VERSION "pcm-protocol-0.4"

NS_ :

BS_:

BU_: HOST PCM0 PCM1

VAL_TABLE_ OutRequest 3 "RESERVED" 2 "ON" 1 "OFF" 0 "RELEASE" ;
VAL_TABLE_ OutState 3 "FAULT" 2 "PWM" 1 "ON" 0 "OFF" ;
VAL_TABLE_ OutSource 3 "OVERRIDE" 2 "CAN" 1 "RULE" 0 "DEFAULT" ;
VAL_TABLE_ SlotClass 3 "L" 2 "M" 1 "S" 0 "EMPTY" ;
VAL_TABLE_ FaultCode 13 "OVERVOLTAGE" 12 "FEEDBACK_MISMATCH" 11 "RUN_LIMIT" 10 "RETRY_WAIT" 9 "SLOT_MISMATCH" 8 "UNDERVOLTAGE" 7 "LOAD_SHED" 6 "LATCHED" 5 "EXT_VOLTAGE" 4 "OPEN_LOAD" 3 "OVERTEMP" 2 "SHORT" 1 "OVERCURRENT" 0 "NONE" ;
VAL_TABLE_ ConfigOp 5 "FACTORY_RESET" 4 "REVERT" 3 "COMMIT" 2 "WRITE" 1 "READ" 0 "NOP" ;
VAL_TABLE_ ConfigStatus 5 "LOCKED" 4 "BUSY" 3 "READ_ONLY" 2 "OUT_OF_RANGE" 1 "UNKNOWN_PARAM" 0 "OK" ;
VAL_TABLE_ ResetReason 5 "FW_UPDATE" 4 "PIN" 3 "SOFTWARE" 2 "WATCHDOG" 1 "BROWN_OUT" 0 "POWER_ON" ;

BO_ 1696 PCM0_Command: 8 HOST
 SG_ OUT1_Req : 0|2@1+ (1,0) [0|3] "" PCM0
 SG_ OUT2_Req : 2|2@1+ (1,0) [0|3] "" PCM0
 SG_ OUT3_Req : 4|2@1+ (1,0) [0|3] "" PCM0
 SG_ OUT4_Req : 6|2@1+ (1,0) [0|3] "" PCM0
 SG_ OUT1_FaultReset : 8|1@1+ (1,0) [0|1] "" PCM0
 SG_ OUT2_FaultReset : 9|1@1+ (1,0) [0|1] "" PCM0
 SG_ OUT3_FaultReset : 10|1@1+ (1,0) [0|1] "" PCM0
 SG_ OUT4_FaultReset : 11|1@1+ (1,0) [0|1] "" PCM0
 SG_ Cmd_AliveCounter : 12|4@1+ (1,0) [0|15] "" PCM0
 SG_ OUT1_Duty : 16|8@1+ (0.5,0) [0|127.5] "%" PCM0
 SG_ OUT2_Duty : 24|8@1+ (0.5,0) [0|127.5] "%" PCM0
 SG_ OUT3_Duty : 32|8@1+ (0.5,0) [0|127.5] "%" PCM0
 SG_ OUT4_Duty : 40|8@1+ (0.5,0) [0|127.5] "%" PCM0
 SG_ VIN1 : 48|1@1+ (1,0) [0|1] "" PCM0
 SG_ VIN2 : 49|1@1+ (1,0) [0|1] "" PCM0
 SG_ VIN3 : 50|1@1+ (1,0) [0|1] "" PCM0
 SG_ VIN4 : 51|1@1+ (1,0) [0|1] "" PCM0
 SG_ VIN5 : 52|1@1+ (1,0) [0|1] "" PCM0
 SG_ VIN6 : 53|1@1+ (1,0) [0|1] "" PCM0
 SG_ VIN7 : 54|1@1+ (1,0) [0|1] "" PCM0
 SG_ VIN8 : 55|1@1+ (1,0) [0|1] "" PCM0
 SG_ AUX1_Req : 56|2@1+ (1,0) [0|3] "" PCM0
 SG_ AUX2_Req : 58|2@1+ (1,0) [0|3] "" PCM0
 SG_ AUX3_Req : 60|2@1+ (1,0) [0|3] "" PCM0
 SG_ AUX4_Req : 62|2@1+ (1,0) [0|3] "" PCM0

BO_ 1697 PCM0_Status: 8 PCM0
 SG_ OUT1_State : 0|2@1+ (1,0) [0|3] "" HOST
 SG_ OUT2_State : 2|2@1+ (1,0) [0|3] "" HOST
 SG_ OUT3_State : 4|2@1+ (1,0) [0|3] "" HOST
 SG_ OUT4_State : 6|2@1+ (1,0) [0|3] "" HOST
 SG_ IN1_Active : 8|1@1+ (1,0) [0|1] "" HOST
 SG_ IN2_Active : 9|1@1+ (1,0) [0|1] "" HOST
 SG_ IN3_Active : 10|1@1+ (1,0) [0|1] "" HOST
 SG_ IN4_Active : 11|1@1+ (1,0) [0|1] "" HOST
 SG_ IN5_Active : 12|1@1+ (1,0) [0|1] "" HOST
 SG_ IN6_Active : 13|1@1+ (1,0) [0|1] "" HOST
 SG_ IN7_Active : 14|1@1+ (1,0) [0|1] "" HOST
 SG_ IN8_Active : 15|1@1+ (1,0) [0|1] "" HOST
 SG_ VBAT : 16|8@1+ (0.1,0) [0|25.5] "V" HOST
 SG_ BoardTemp : 24|8@1+ (1,-40) [-40|215] "degC" HOST
 SG_ OUT1_Source : 32|2@1+ (1,0) [0|3] "" HOST
 SG_ OUT2_Source : 34|2@1+ (1,0) [0|3] "" HOST
 SG_ OUT3_Source : 36|2@1+ (1,0) [0|3] "" HOST
 SG_ OUT4_Source : 38|2@1+ (1,0) [0|3] "" HOST
 SG_ IGN_Active : 40|1@1+ (1,0) [0|1] "" HOST
 SG_ SleepPending : 41|1@1+ (1,0) [0|1] "" HOST
 SG_ HostPresent : 42|1@1+ (1,0) [0|1] "" HOST
 SG_ ConfigDirty : 43|1@1+ (1,0) [0|1] "" HOST
 SG_ LoadShedActive : 44|1@1+ (1,0) [0|1] "" HOST
 SG_ ModuleBudgetLimit : 45|1@1+ (1,0) [0|1] "" HOST
 SG_ ThermalDerating : 46|1@1+ (1,0) [0|1] "" HOST
 SG_ VehicleSignalStale : 47|1@1+ (1,0) [0|1] "" HOST
 SG_ ModuleCurrent : 48|8@1+ (0.5,0) [0|127.5] "A" HOST
 SG_ AUX1_On : 56|1@1+ (1,0) [0|1] "" HOST
 SG_ AUX2_On : 57|1@1+ (1,0) [0|1] "" HOST
 SG_ AUX3_On : 58|1@1+ (1,0) [0|1] "" HOST
 SG_ AUX4_On : 59|1@1+ (1,0) [0|1] "" HOST
 SG_ Sts_AliveCounter : 60|4@1+ (1,0) [0|15] "" HOST

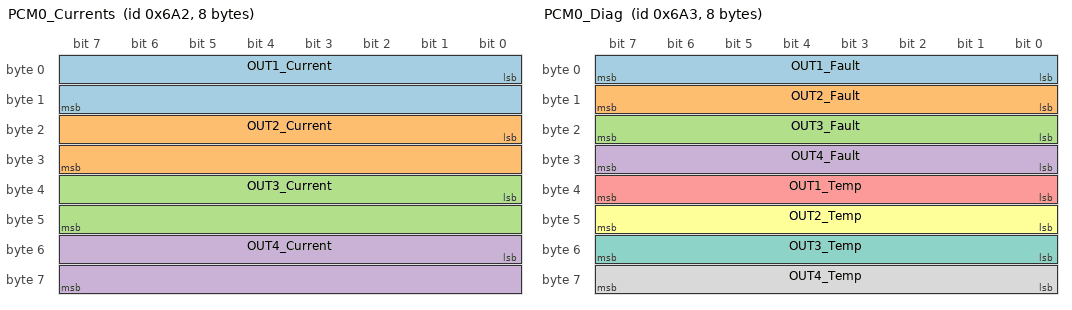
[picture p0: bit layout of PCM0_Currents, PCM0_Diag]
BO_ 1698 PCM0_Currents: 8 PCM0
 SG_ OUT1_Current : 0|16@1+ (0.01,0) [0|655.35] "A" HOST
 SG_ OUT2_Current : 16|16@1+ (0.01,0) [0|655.35] "A" HOST
 SG_ OUT3_Current : 32|16@1+ (0.01,0) [0|655.35] "A" HOST
 SG_ OUT4_Current : 48|16@1+ (0.01,0) [0|655.35] "A" HOST

BO_ 1699 PCM0_Diag: 8 PCM0
 SG_ OUT1_Fault : 0|8@1+ (1,0) [0|255] "" HOST
 SG_ OUT2_Fault : 8|8@1+ (1,0) [0|255] "" HOST
 SG_ OUT3_Fault : 16|8@1+ (1,0) [0|255] "" HOST
 SG_ OUT4_Fault : 24|8@1+ (1,0) [0|255] "" HOST
 SG_ OUT1_Temp : 32|8@1+ (1,-40) [-40|215] "degC" HOST
 SG_ OUT2_Temp : 40|8@1+ (1,-40) [-40|215] "degC" HOST
 SG_ OUT3_Temp : 48|8@1+ (1,-40) [-40|215] "degC" HOST
 SG_ OUT4_Temp : 56|8@1+ (1,-40) [-40|215] "degC" HOST

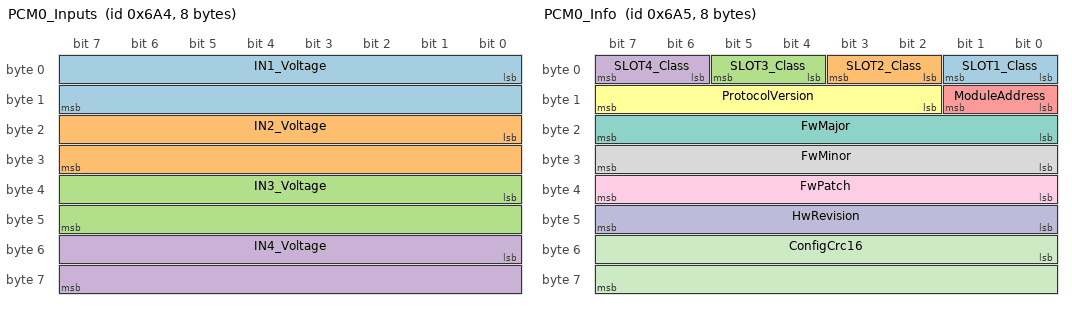
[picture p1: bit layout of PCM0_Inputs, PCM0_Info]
BO_ 1700 PCM0_Inputs: 8 PCM0
 SG_ IN1_Voltage : 0|16@1+ (0.001,0) [0|65.535] "V" HOST
 SG_ IN2_Voltage : 16|16@1+ (0.001,0) [0|65.535] "V" HOST
 SG_ IN3_Voltage : 32|16@1+ (0.001,0) [0|65.535] "V" HOST
 SG_ IN4_Voltage : 48|16@1+ (0.001,0) [0|65.535] "V" HOST

BO_ 1701 PCM0_Info: 8 PCM0
 SG_ SLOT1_Class : 0|2@1+ (1,0) [0|3] "" HOST
 SG_ SLOT2_Class : 2|2@1+ (1,0) [0|3] "" HOST
 SG_ SLOT3_Class : 4|2@1+ (1,0) [0|3] "" HOST
 SG_ SLOT4_Class : 6|2@1+ (1,0) [0|3] "" HOST
 SG_ ModuleAddress : 8|2@1+ (1,0) [0|3] "" HOST
 SG_ ProtocolVersion : 10|6@1+ (1,0) [0|63] "" HOST
 SG_ FwMajor : 16|8@1+ (1,0) [0|255] "" HOST
 SG_ FwMinor : 24|8@1+ (1,0) [0|255] "" HOST
 SG_ FwPatch : 32|8@1+ (1,0) [0|255] "" HOST
 SG_ HwRevision : 40|8@1+ (1,0) [0|255] "" HOST
 SG_ ConfigCrc16 : 48|16@1+ (1,0) [0|65535] "" HOST

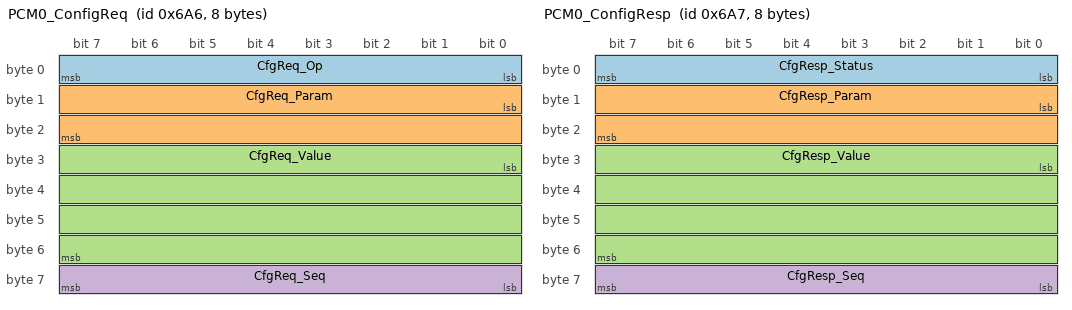
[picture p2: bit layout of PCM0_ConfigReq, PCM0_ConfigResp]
BO_ 1702 PCM0_ConfigReq: 8 HOST
 SG_ CfgReq_Op : 0|8@1+ (1,0) [0|255] "" PCM0
 SG_ CfgReq_Param : 8|16@1+ (1,0) [0|65535] "" PCM0
 SG_ CfgReq_Value : 24|32@1- (1,0) [-2147483648|2147483647] "" PCM0
 SG_ CfgReq_Seq : 56|8@1+ (1,0) [0|255] "" PCM0

BO_ 1703 PCM0_ConfigResp: 8 PCM0
 SG_ CfgResp_Status : 0|8@1+ (1,0) [0|255] "" HOST
 SG_ CfgResp_Param : 8|16@1+ (1,0) [0|65535] "" HOST
 SG_ CfgResp_Value : 24|32@1- (1,0) [-2147483648|2147483647] "" HOST
 SG_ CfgResp_Seq : 56|8@1+ (1,0) [0|255] "" HOST

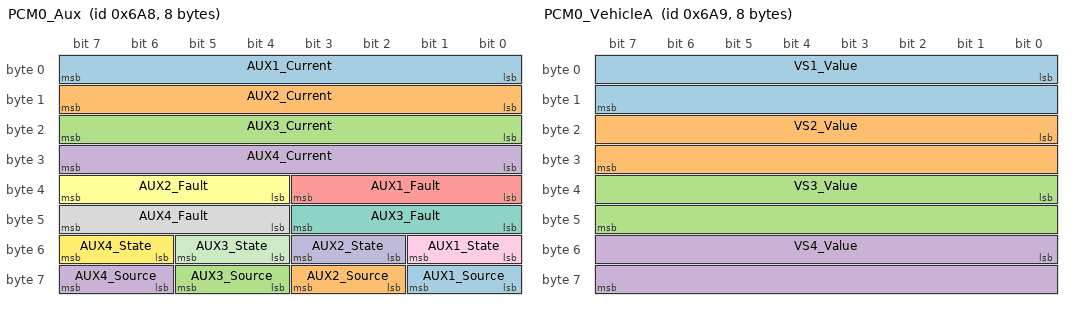
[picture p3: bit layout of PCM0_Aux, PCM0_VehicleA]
BO_ 1704 PCM0_Aux: 8 PCM0
 SG_ AUX1_Current : 0|8@1+ (0.02,0) [0|5.1] "A" HOST
 SG_ AUX2_Current : 8|8@1+ (0.02,0) [0|5.1] "A" HOST
 SG_ AUX3_Current : 16|8@1+ (0.02,0) [0|5.1] "A" HOST
 SG_ AUX4_Current : 24|8@1+ (0.02,0) [0|5.1] "A" HOST
 SG_ AUX1_Fault : 32|4@1+ (1,0) [0|15] "" HOST
 SG_ AUX2_Fault : 36|4@1+ (1,0) [0|15] "" HOST
 SG_ AUX3_Fault : 40|4@1+ (1,0) [0|15] "" HOST
 SG_ AUX4_Fault : 44|4@1+ (1,0) [0|15] "" HOST
 SG_ AUX1_State : 48|2@1+ (1,0) [0|3] "" HOST
 SG_ AUX2_State : 50|2@1+ (1,0) [0|3] "" HOST
 SG_ AUX3_State : 52|2@1+ (1,0) [0|3] "" HOST
 SG_ AUX4_State : 54|2@1+ (1,0) [0|3] "" HOST
 SG_ AUX1_Source : 56|2@1+ (1,0) [0|3] "" HOST
 SG_ AUX2_Source : 58|2@1+ (1,0) [0|3] "" HOST
 SG_ AUX3_Source : 60|2@1+ (1,0) [0|3] "" HOST
 SG_ AUX4_Source : 62|2@1+ (1,0) [0|3] "" HOST

BO_ 1705 PCM0_VehicleA: 8 PCM0
 SG_ VS1_Value : 0|16@1- (1,0) [-32768|32767] "" HOST
 SG_ VS2_Value : 16|16@1- (1,0) [-32768|32767] "" HOST
 SG_ VS3_Value : 32|16@1- (1,0) [-32768|32767] "" HOST
 SG_ VS4_Value : 48|16@1- (1,0) [-32768|32767] "" HOST

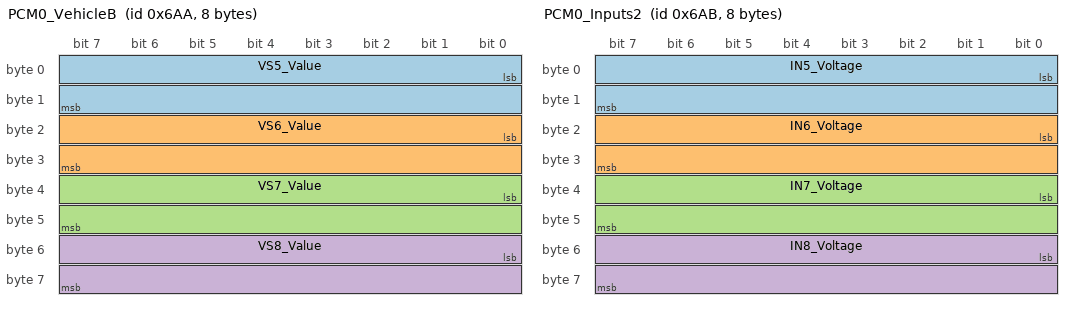
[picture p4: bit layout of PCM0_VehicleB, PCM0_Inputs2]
BO_ 1706 PCM0_VehicleB: 8 PCM0
 SG_ VS5_Value : 0|16@1- (1,0) [-32768|32767] "" HOST
 SG_ VS6_Value : 16|16@1- (1,0) [-32768|32767] "" HOST
 SG_ VS7_Value : 32|16@1- (1,0) [-32768|32767] "" HOST
 SG_ VS8_Value : 48|16@1- (1,0) [-32768|32767] "" HOST

BO_ 1707 PCM0_Inputs2: 8 PCM0
 SG_ IN5_Voltage : 0|16@1+ (0.001,0) [0|65.535] "V" HOST
 SG_ IN6_Voltage : 16|16@1+ (0.001,0) [0|65.535] "V" HOST
 SG_ IN7_Voltage : 32|16@1+ (0.001,0) [0|65.535] "V" HOST
 SG_ IN8_Voltage : 48|16@1+ (0.001,0) [0|65.535] "V" HOST

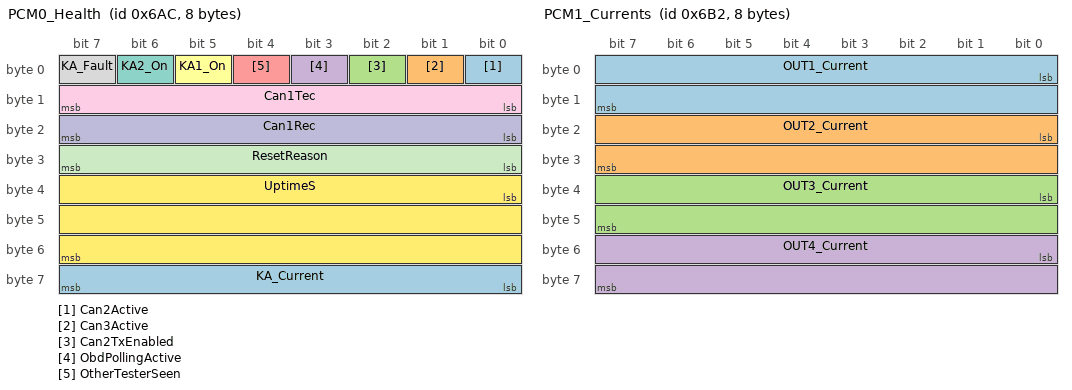
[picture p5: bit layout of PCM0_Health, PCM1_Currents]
BO_ 1708 PCM0_Health: 8 PCM0
 SG_ Can2Active : 0|1@1+ (1,0) [0|1] "" HOST
 SG_ Can3Active : 1|1@1+ (1,0) [0|1] "" HOST
 SG_ Can2TxEnabled : 2|1@1+ (1,0) [0|1] "" HOST
 SG_ ObdPollingActive : 3|1@1+ (1,0) [0|1] "" HOST
 SG_ OtherTesterSeen : 4|1@1+ (1,0) [0|1] "" HOST
 SG_ KA1_On : 5|1@1+ (1,0) [0|1] "" HOST
 SG_ KA2_On : 6|1@1+ (1,0) [0|1] "" HOST
 SG_ KA_Fault : 7|1@1+ (1,0) [0|1] "" HOST
 SG_ Can1Tec : 8|8@1+ (1,0) [0|255] "" HOST
 SG_ Can1Rec : 16|8@1+ (1,0) [0|255] "" HOST
 SG_ ResetReason : 24|8@1+ (1,0) [0|255] "" HOST
 SG_ UptimeS : 32|24@1+ (1,0) [0|16777215] "s" HOST
 SG_ KA_Current : 56|8@1+ (0.005,0) [0|1.275] "A" HOST

BO_ 1712 PCM1_Command: 8 HOST
 SG_ OUT1_Req : 0|2@1+ (1,0) [0|3] "" PCM1
 SG_ OUT2_Req : 2|2@1+ (1,0) [0|3] "" PCM1
 SG_ OUT3_Req : 4|2@1+ (1,0) [0|3] "" PCM1
 SG_ OUT4_Req : 6|2@1+ (1,0) [0|3] "" PCM1
 SG_ OUT1_FaultReset : 8|1@1+ (1,0) [0|1] "" PCM1
 SG_ OUT2_FaultReset : 9|1@1+ (1,0) [0|1] "" PCM1
 SG_ OUT3_FaultReset : 10|1@1+ (1,0) [0|1] "" PCM1
 SG_ OUT4_FaultReset : 11|1@1+ (1,0) [0|1] "" PCM1
 SG_ Cmd_AliveCounter : 12|4@1+ (1,0) [0|15] "" PCM1
 SG_ OUT1_Duty : 16|8@1+ (0.5,0) [0|127.5] "%" PCM1
 SG_ OUT2_Duty : 24|8@1+ (0.5,0) [0|127.5] "%" PCM1
 SG_ OUT3_Duty : 32|8@1+ (0.5,0) [0|127.5] "%" PCM1
 SG_ OUT4_Duty : 40|8@1+ (0.5,0) [0|127.5] "%" PCM1
 SG_ VIN1 : 48|1@1+ (1,0) [0|1] "" PCM1
 SG_ VIN2 : 49|1@1+ (1,0) [0|1] "" PCM1
 SG_ VIN3 : 50|1@1+ (1,0) [0|1] "" PCM1
 SG_ VIN4 : 51|1@1+ (1,0) [0|1] "" PCM1
 SG_ VIN5 : 52|1@1+ (1,0) [0|1] "" PCM1
 SG_ VIN6 : 53|1@1+ (1,0) [0|1] "" PCM1
 SG_ VIN7 : 54|1@1+ (1,0) [0|1] "" PCM1
 SG_ VIN8 : 55|1@1+ (1,0) [0|1] "" PCM1
 SG_ AUX1_Req : 56|2@1+ (1,0) [0|3] "" PCM1
 SG_ AUX2_Req : 58|2@1+ (1,0) [0|3] "" PCM1
 SG_ AUX3_Req : 60|2@1+ (1,0) [0|3] "" PCM1
 SG_ AUX4_Req : 62|2@1+ (1,0) [0|3] "" PCM1

BO_ 1713 PCM1_Status: 8 PCM1
 SG_ OUT1_State : 0|2@1+ (1,0) [0|3] "" HOST
 SG_ OUT2_State : 2|2@1+ (1,0) [0|3] "" HOST
 SG_ OUT3_State : 4|2@1+ (1,0) [0|3] "" HOST
 SG_ OUT4_State : 6|2@1+ (1,0) [0|3] "" HOST
 SG_ IN1_Active : 8|1@1+ (1,0) [0|1] "" HOST
 SG_ IN2_Active : 9|1@1+ (1,0) [0|1] "" HOST
 SG_ IN3_Active : 10|1@1+ (1,0) [0|1] "" HOST
 SG_ IN4_Active : 11|1@1+ (1,0) [0|1] "" HOST
 SG_ IN5_Active : 12|1@1+ (1,0) [0|1] "" HOST
 SG_ IN6_Active : 13|1@1+ (1,0) [0|1] "" HOST
 SG_ IN7_Active : 14|1@1+ (1,0) [0|1] "" HOST
 SG_ IN8_Active : 15|1@1+ (1,0) [0|1] "" HOST
 SG_ VBAT : 16|8@1+ (0.1,0) [0|25.5] "V" HOST
 SG_ BoardTemp : 24|8@1+ (1,-40) [-40|215] "degC" HOST
 SG_ OUT1_Source : 32|2@1+ (1,0) [0|3] "" HOST
 SG_ OUT2_Source : 34|2@1+ (1,0) [0|3] "" HOST
 SG_ OUT3_Source : 36|2@1+ (1,0) [0|3] "" HOST
 SG_ OUT4_Source : 38|2@1+ (1,0) [0|3] "" HOST
 SG_ IGN_Active : 40|1@1+ (1,0) [0|1] "" HOST
 SG_ SleepPending : 41|1@1+ (1,0) [0|1] "" HOST
 SG_ HostPresent : 42|1@1+ (1,0) [0|1] "" HOST
 SG_ ConfigDirty : 43|1@1+ (1,0) [0|1] "" HOST
 SG_ LoadShedActive : 44|1@1+ (1,0) [0|1] "" HOST
 SG_ ModuleBudgetLimit : 45|1@1+ (1,0) [0|1] "" HOST
 SG_ ThermalDerating : 46|1@1+ (1,0) [0|1] "" HOST
 SG_ VehicleSignalStale : 47|1@1+ (1,0) [0|1] "" HOST
 SG_ ModuleCurrent : 48|8@1+ (0.5,0) [0|127.5] "A" HOST
 SG_ AUX1_On : 56|1@1+ (1,0) [0|1] "" HOST
 SG_ AUX2_On : 57|1@1+ (1,0) [0|1] "" HOST
 SG_ AUX3_On : 58|1@1+ (1,0) [0|1] "" HOST
 SG_ AUX4_On : 59|1@1+ (1,0) [0|1] "" HOST
 SG_ Sts_AliveCounter : 60|4@1+ (1,0) [0|15] "" HOST

BO_ 1714 PCM1_Currents: 8 PCM1
 SG_ OUT1_Current : 0|16@1+ (0.01,0) [0|655.35] "A" HOST
 SG_ OUT2_Current : 16|16@1+ (0.01,0) [0|655.35] "A" HOST
 SG_ OUT3_Current : 32|16@1+ (0.01,0) [0|655.35] "A" HOST
 SG_ OUT4_Current : 48|16@1+ (0.01,0) [0|655.35] "A" HOST

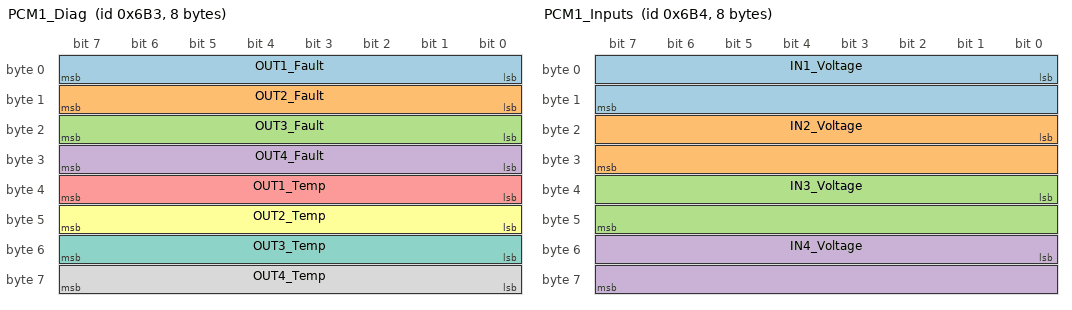
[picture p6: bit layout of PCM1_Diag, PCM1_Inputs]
BO_ 1715 PCM1_Diag: 8 PCM1
 SG_ OUT1_Fault : 0|8@1+ (1,0) [0|255] "" HOST
 SG_ OUT2_Fault : 8|8@1+ (1,0) [0|255] "" HOST
 SG_ OUT3_Fault : 16|8@1+ (1,0) [0|255] "" HOST
 SG_ OUT4_Fault : 24|8@1+ (1,0) [0|255] "" HOST
 SG_ OUT1_Temp : 32|8@1+ (1,-40) [-40|215] "degC" HOST
 SG_ OUT2_Temp : 40|8@1+ (1,-40) [-40|215] "degC" HOST
 SG_ OUT3_Temp : 48|8@1+ (1,-40) [-40|215] "degC" HOST
 SG_ OUT4_Temp : 56|8@1+ (1,-40) [-40|215] "degC" HOST

BO_ 1716 PCM1_Inputs: 8 PCM1
 SG_ IN1_Voltage : 0|16@1+ (0.001,0) [0|65.535] "V" HOST
 SG_ IN2_Voltage : 16|16@1+ (0.001,0) [0|65.535] "V" HOST
 SG_ IN3_Voltage : 32|16@1+ (0.001,0) [0|65.535] "V" HOST
 SG_ IN4_Voltage : 48|16@1+ (0.001,0) [0|65.535] "V" HOST

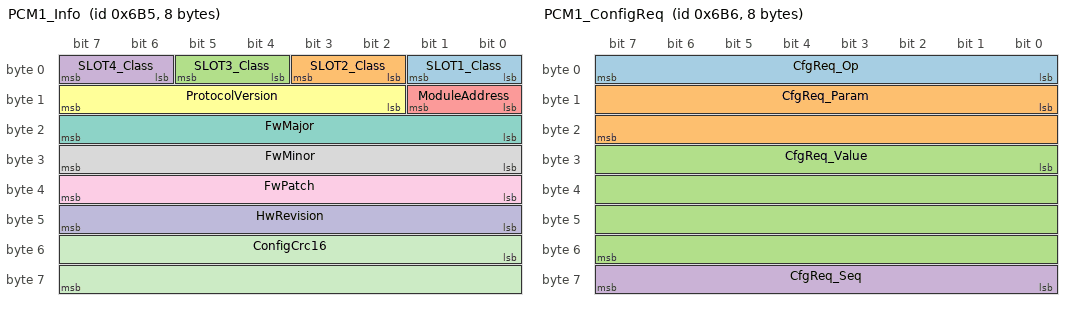
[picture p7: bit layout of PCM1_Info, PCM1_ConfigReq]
BO_ 1717 PCM1_Info: 8 PCM1
 SG_ SLOT1_Class : 0|2@1+ (1,0) [0|3] "" HOST
 SG_ SLOT2_Class : 2|2@1+ (1,0) [0|3] "" HOST
 SG_ SLOT3_Class : 4|2@1+ (1,0) [0|3] "" HOST
 SG_ SLOT4_Class : 6|2@1+ (1,0) [0|3] "" HOST
 SG_ ModuleAddress : 8|2@1+ (1,0) [0|3] "" HOST
 SG_ ProtocolVersion : 10|6@1+ (1,0) [0|63] "" HOST
 SG_ FwMajor : 16|8@1+ (1,0) [0|255] "" HOST
 SG_ FwMinor : 24|8@1+ (1,0) [0|255] "" HOST
 SG_ FwPatch : 32|8@1+ (1,0) [0|255] "" HOST
 SG_ HwRevision : 40|8@1+ (1,0) [0|255] "" HOST
 SG_ ConfigCrc16 : 48|16@1+ (1,0) [0|65535] "" HOST

BO_ 1718 PCM1_ConfigReq: 8 HOST
 SG_ CfgReq_Op : 0|8@1+ (1,0) [0|255] "" PCM1
 SG_ CfgReq_Param : 8|16@1+ (1,0) [0|65535] "" PCM1
 SG_ CfgReq_Value : 24|32@1- (1,0) [-2147483648|2147483647] "" PCM1
 SG_ CfgReq_Seq : 56|8@1+ (1,0) [0|255] "" PCM1

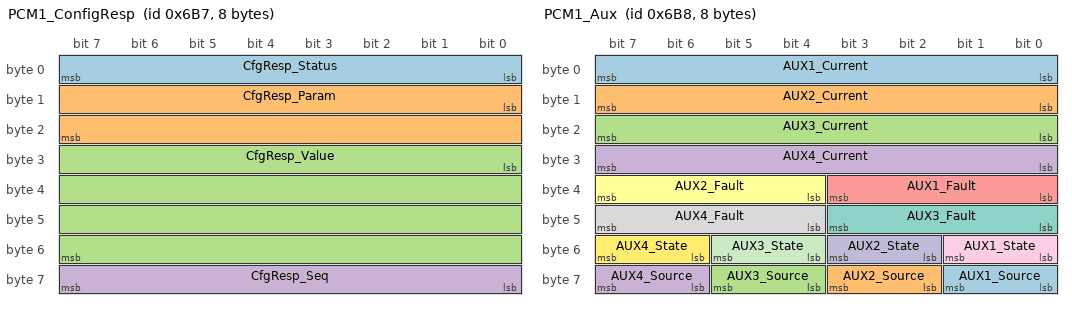
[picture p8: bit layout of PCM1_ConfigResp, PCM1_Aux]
BO_ 1719 PCM1_ConfigResp: 8 PCM1
 SG_ CfgResp_Status : 0|8@1+ (1,0) [0|255] "" HOST
 SG_ CfgResp_Param : 8|16@1+ (1,0) [0|65535] "" HOST
 SG_ CfgResp_Value : 24|32@1- (1,0) [-2147483648|2147483647] "" HOST
 SG_ CfgResp_Seq : 56|8@1+ (1,0) [0|255] "" HOST

BO_ 1720 PCM1_Aux: 8 PCM1
 SG_ AUX1_Current : 0|8@1+ (0.02,0) [0|5.1] "A" HOST
 SG_ AUX2_Current : 8|8@1+ (0.02,0) [0|5.1] "A" HOST
 SG_ AUX3_Current : 16|8@1+ (0.02,0) [0|5.1] "A" HOST
 SG_ AUX4_Current : 24|8@1+ (0.02,0) [0|5.1] "A" HOST
 SG_ AUX1_Fault : 32|4@1+ (1,0) [0|15] "" HOST
 SG_ AUX2_Fault : 36|4@1+ (1,0) [0|15] "" HOST
 SG_ AUX3_Fault : 40|4@1+ (1,0) [0|15] "" HOST
 SG_ AUX4_Fault : 44|4@1+ (1,0) [0|15] "" HOST
 SG_ AUX1_State : 48|2@1+ (1,0) [0|3] "" HOST
 SG_ AUX2_State : 50|2@1+ (1,0) [0|3] "" HOST
 SG_ AUX3_State : 52|2@1+ (1,0) [0|3] "" HOST
 SG_ AUX4_State : 54|2@1+ (1,0) [0|3] "" HOST
 SG_ AUX1_Source : 56|2@1+ (1,0) [0|3] "" HOST
 SG_ AUX2_Source : 58|2@1+ (1,0) [0|3] "" HOST
 SG_ AUX3_Source : 60|2@1+ (1,0) [0|3] "" HOST
 SG_ AUX4_Source : 62|2@1+ (1,0) [0|3] "" HOST

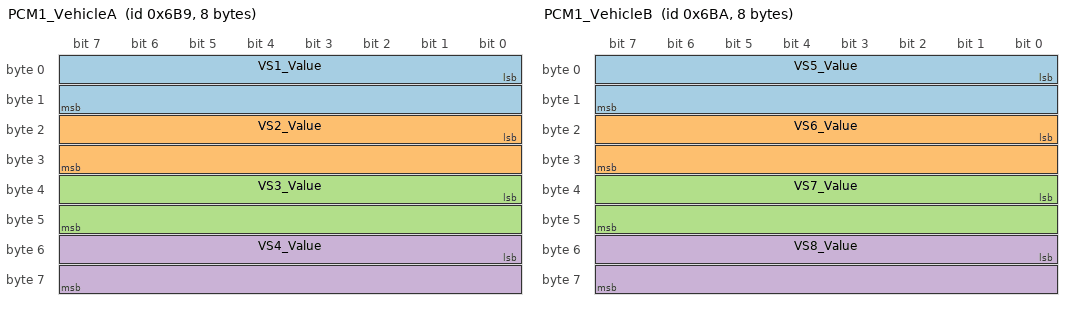
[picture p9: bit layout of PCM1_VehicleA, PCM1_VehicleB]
BO_ 1721 PCM1_VehicleA: 8 PCM1
 SG_ VS1_Value : 0|16@1- (1,0) [-32768|32767] "" HOST
 SG_ VS2_Value : 16|16@1- (1,0) [-32768|32767] "" HOST
 SG_ VS3_Value : 32|16@1- (1,0) [-32768|32767] "" HOST
 SG_ VS4_Value : 48|16@1- (1,0) [-32768|32767] "" HOST

BO_ 1722 PCM1_VehicleB: 8 PCM1
 SG_ VS5_Value : 0|16@1- (1,0) [-32768|32767] "" HOST
 SG_ VS6_Value : 16|16@1- (1,0) [-32768|32767] "" HOST
 SG_ VS7_Value : 32|16@1- (1,0) [-32768|32767] "" HOST
 SG_ VS8_Value : 48|16@1- (1,0) [-32768|32767] "" HOST

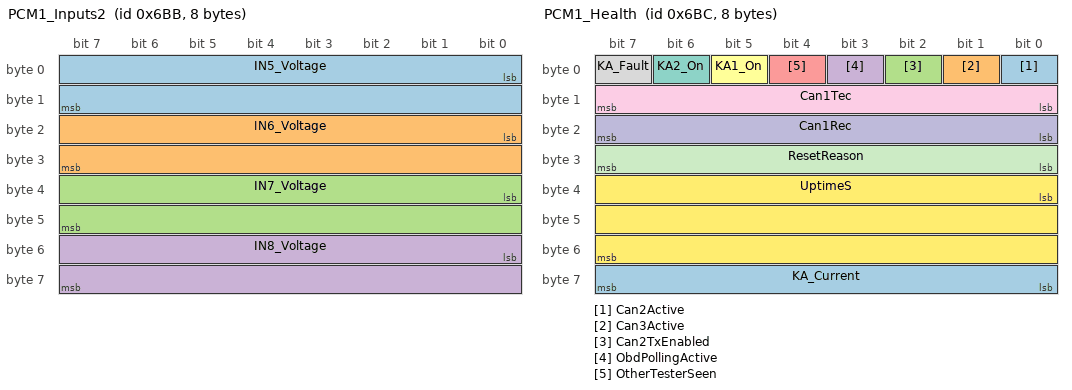
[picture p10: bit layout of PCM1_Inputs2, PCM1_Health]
BO_ 1723 PCM1_Inputs2: 8 PCM1
 SG_ IN5_Voltage : 0|16@1+ (0.001,0) [0|65.535] "V" HOST
 SG_ IN6_Voltage : 16|16@1+ (0.001,0) [0|65.535] "V" HOST
 SG_ IN7_Voltage : 32|16@1+ (0.001,0) [0|65.535] "V" HOST
 SG_ IN8_Voltage : 48|16@1+ (0.001,0) [0|65.535] "V" HOST

BO_ 1724 PCM1_Health: 8 PCM1
 SG_ Can2Active : 0|1@1+ (1,0) [0|1] "" HOST
 SG_ Can3Active : 1|1@1+ (1,0) [0|1] "" HOST
 SG_ Can2TxEnabled : 2|1@1+ (1,0) [0|1] "" HOST
 SG_ ObdPollingActive : 3|1@1+ (1,0) [0|1] "" HOST
 SG_ OtherTesterSeen : 4|1@1+ (1,0) [0|1] "" HOST
 SG_ KA1_On : 5|1@1+ (1,0) [0|1] "" HOST
 SG_ KA2_On : 6|1@1+ (1,0) [0|1] "" HOST
 SG_ KA_Fault : 7|1@1+ (1,0) [0|1] "" HOST
 SG_ Can1Tec : 8|8@1+ (1,0) [0|255] "" HOST
 SG_ Can1Rec : 16|8@1+ (1,0) [0|255] "" HOST
 SG_ ResetReason : 24|8@1+ (1,0) [0|255] "" HOST
 SG_ UptimeS : 32|24@1+ (1,0) [0|16777215] "s" HOST
 SG_ KA_Current : 56|8@1+ (0.005,0) [0|1.275] "A" HOST

CM_ "Power control modules, addresses 0-1, default base ID 0x6A0; module n uses base + 0x10*n. Generated from pcm.dbc by tools/gen_dbc.py - edit pcm.dbc, not this file.";
CM_ BO_ 1696 "Host to module. Send every 100 ms while controlling outputs; 500 ms without a frame whose alive counter changed is a host timeout.";
CM_ BO_ 1712 "Host to module. Send every 100 ms while controlling outputs; 500 ms without a frame whose alive counter changed is a host timeout.";
CM_ SG_ 1696 OUT1_Req "RELEASE hands the output back to the rule engine.";
CM_ SG_ 1712 OUT1_Req "RELEASE hands the output back to the rule engine.";
CM_ SG_ 1696 OUT1_Duty "PWM duty when Req is ON. 200 = 100 %. 255 = use the configured default.";
CM_ SG_ 1712 OUT1_Duty "PWM duty when Req is ON. 200 = 100 %. 255 = use the configured default.";
CM_ SG_ 1696 OUT1_FaultReset "Rising edge clears a latched fault on OUT1.";
CM_ SG_ 1712 OUT1_FaultReset "Rising edge clears a latched fault on OUT1.";
CM_ SG_ 1696 Cmd_AliveCounter "Increment by 1 every frame, wrapping at 15.";
CM_ SG_ 1712 Cmd_AliveCounter "Increment by 1 every frame, wrapping at 15.";
CM_ SG_ 1696 VIN1 "Virtual input for the rule engine, e.g. a CAN switch-panel button.";
CM_ SG_ 1712 VIN1 "Virtual input for the rule engine, e.g. a CAN switch-panel button.";
CM_ SG_ 1696 AUX1_Req "Same coding as OUT1_Req. AUX outputs are on/off only.";
CM_ SG_ 1712 AUX1_Req "Same coding as OUT1_Req. AUX outputs are on/off only.";
CM_ BO_ 1697 "Module to host. 100 ms, and on any state change (at most every 10 ms).";
CM_ BO_ 1713 "Module to host. 100 ms, and on any state change (at most every 10 ms).";
CM_ SG_ 1697 ConfigDirty "RAM configuration differs from flash; send ConfigReq COMMIT to persist.";
CM_ SG_ 1713 ConfigDirty "RAM configuration differs from flash; send ConfigReq COMMIT to persist.";
CM_ SG_ 1697 ModuleCurrent "Sum of all main and AUX output currents.";
CM_ SG_ 1713 ModuleCurrent "Sum of all main and AUX output currents.";
CM_ BO_ 1698 "Module to host, 100 ms.";
CM_ BO_ 1714 "Module to host, 100 ms.";
CM_ BO_ 1699 "Module to host, 1 s and on change. Temp 255 (raw) = not measured for this cell.";
CM_ BO_ 1715 "Module to host, 1 s and on change. Temp 255 (raw) = not measured for this cell.";
CM_ SG_ 1699 OUT1_Fault "FaultCode value table.";
CM_ SG_ 1715 OUT1_Fault "FaultCode value table.";
CM_ BO_ 1700 "Module to host, 100 ms. Voltage at input pins 1-4.";
CM_ BO_ 1716 "Module to host, 100 ms. Voltage at input pins 1-4.";
CM_ BO_ 1701 "Module to host, 1 s.";
CM_ BO_ 1717 "Module to host, 1 s.";
CM_ BO_ 1702 "Host to module configuration access. One request in flight; match responses by Seq.";
CM_ BO_ 1718 "Host to module configuration access. One request in flight; match responses by Seq.";
CM_ BO_ 1703 "Module to host, reply to ConfigReq.";
CM_ BO_ 1719 "Module to host, reply to ConfigReq.";
CM_ BO_ 1704 "Module to host, 100 ms. AUX coil-driver bank.";
CM_ BO_ 1720 "Module to host, 100 ms. AUX coil-driver bank.";
CM_ SG_ 1704 AUX1_Fault "FaultCode value table, codes 0-15.";
CM_ SG_ 1720 AUX1_Fault "FaultCode value table, codes 0-15.";
CM_ BO_ 1705 "Module to host, 100 ms when vehicle signals are configured. Value in the units set by each signal's scale in the configuration; -32768 = stale or not configured.";
CM_ BO_ 1721 "Module to host, 100 ms when vehicle signals are configured. Value in the units set by each signal's scale in the configuration; -32768 = stale or not configured.";
CM_ BO_ 1706 "As VehicleA, for VS5-VS8.";
CM_ BO_ 1722 "As VehicleA, for VS5-VS8.";
CM_ BO_ 1707 "Module to host, 100 ms. Voltage at input pins 5-8.";
CM_ BO_ 1723 "Module to host, 100 ms. Voltage at input pins 5-8.";
CM_ BO_ 1708 "Module to host, 1 s. Bus and processor health.";
CM_ BO_ 1724 "Module to host, 1 s. Bus and processor health.";
CM_ SG_ 1708 Can2TxEnabled "The OBD-port transmit link is fitted and enabled in configuration.";
CM_ SG_ 1724 Can2TxEnabled "The OBD-port transmit link is fitted and enabled in configuration.";
CM_ SG_ 1708 OtherTesterSeen "Another diagnostic tester is active on the OBD port; polling is paused.";
CM_ SG_ 1724 OtherTesterSeen "Another diagnostic tester is active on the OBD port; polling is paused.";
CM_ SG_ 1708 KA_Fault "A keep-alive output tripped, or its current is outside the configured band.";
CM_ SG_ 1724 KA_Fault "A keep-alive output tripped, or its current is outside the configured band.";
CM_ SG_ 1708 KA_Current "Total keep-alive current, both outputs.";
CM_ SG_ 1724 KA_Current "Total keep-alive current, both outputs.";

BA_DEF_ BO_ "GenMsgCycleTime" INT 0 10000;
BA_DEF_DEF_ "GenMsgCycleTime" 0;
BA_ "GenMsgCycleTime" BO_ 1696 100;
BA_ "GenMsgCycleTime" BO_ 1712 100;
BA_ "GenMsgCycleTime" BO_ 1697 100;
BA_ "GenMsgCycleTime" BO_ 1713 100;
BA_ "GenMsgCycleTime" BO_ 1698 100;
BA_ "GenMsgCycleTime" BO_ 1714 100;
BA_ "GenMsgCycleTime" BO_ 1699 1000;
BA_ "GenMsgCycleTime" BO_ 1715 1000;
BA_ "GenMsgCycleTime" BO_ 1700 100;
BA_ "GenMsgCycleTime" BO_ 1716 100;
BA_ "GenMsgCycleTime" BO_ 1701 1000;
BA_ "GenMsgCycleTime" BO_ 1717 1000;
BA_ "GenMsgCycleTime" BO_ 1704 100;
BA_ "GenMsgCycleTime" BO_ 1720 100;
BA_ "GenMsgCycleTime" BO_ 1705 100;
BA_ "GenMsgCycleTime" BO_ 1721 100;
BA_ "GenMsgCycleTime" BO_ 1706 100;
BA_ "GenMsgCycleTime" BO_ 1722 100;
BA_ "GenMsgCycleTime" BO_ 1707 100;
BA_ "GenMsgCycleTime" BO_ 1723 100;
BA_ "GenMsgCycleTime" BO_ 1708 1000;
BA_ "GenMsgCycleTime" BO_ 1724 1000;

VAL_ 1696 OUT1_Req 3 "RESERVED" 2 "ON" 1 "OFF" 0 "RELEASE" ;
VAL_ 1712 OUT1_Req 3 "RESERVED" 2 "ON" 1 "OFF" 0 "RELEASE" ;
VAL_ 1696 OUT2_Req 3 "RESERVED" 2 "ON" 1 "OFF" 0 "RELEASE" ;
VAL_ 1712 OUT2_Req 3 "RESERVED" 2 "ON" 1 "OFF" 0 "RELEASE" ;
VAL_ 1696 OUT3_Req 3 "RESERVED" 2 "ON" 1 "OFF" 0 "RELEASE" ;
VAL_ 1712 OUT3_Req 3 "RESERVED" 2 "ON" 1 "OFF" 0 "RELEASE" ;
VAL_ 1696 OUT4_Req 3 "RESERVED" 2 "ON" 1 "OFF" 0 "RELEASE" ;
VAL_ 1712 OUT4_Req 3 "RESERVED" 2 "ON" 1 "OFF" 0 "RELEASE" ;
VAL_ 1696 AUX1_Req 3 "RESERVED" 2 "ON" 1 "OFF" 0 "RELEASE" ;
VAL_ 1712 AUX1_Req 3 "RESERVED" 2 "ON" 1 "OFF" 0 "RELEASE" ;
VAL_ 1696 AUX2_Req 3 "RESERVED" 2 "ON" 1 "OFF" 0 "RELEASE" ;
VAL_ 1712 AUX2_Req 3 "RESERVED" 2 "ON" 1 "OFF" 0 "RELEASE" ;
VAL_ 1696 AUX3_Req 3 "RESERVED" 2 "ON" 1 "OFF" 0 "RELEASE" ;
VAL_ 1712 AUX3_Req 3 "RESERVED" 2 "ON" 1 "OFF" 0 "RELEASE" ;
VAL_ 1696 AUX4_Req 3 "RESERVED" 2 "ON" 1 "OFF" 0 "RELEASE" ;
VAL_ 1712 AUX4_Req 3 "RESERVED" 2 "ON" 1 "OFF" 0 "RELEASE" ;
VAL_ 1697 OUT1_State 3 "FAULT" 2 "PWM" 1 "ON" 0 "OFF" ;
VAL_ 1713 OUT1_State 3 "FAULT" 2 "PWM" 1 "ON" 0 "OFF" ;
VAL_ 1697 OUT2_State 3 "FAULT" 2 "PWM" 1 "ON" 0 "OFF" ;
VAL_ 1713 OUT2_State 3 "FAULT" 2 "PWM" 1 "ON" 0 "OFF" ;
VAL_ 1697 OUT3_State 3 "FAULT" 2 "PWM" 1 "ON" 0 "OFF" ;
VAL_ 1713 OUT3_State 3 "FAULT" 2 "PWM" 1 "ON" 0 "OFF" ;
VAL_ 1697 OUT4_State 3 "FAULT" 2 "PWM" 1 "ON" 0 "OFF" ;
VAL_ 1713 OUT4_State 3 "FAULT" 2 "PWM" 1 "ON" 0 "OFF" ;
VAL_ 1697 OUT1_Source 3 "OVERRIDE" 2 "CAN" 1 "RULE" 0 "DEFAULT" ;
VAL_ 1713 OUT1_Source 3 "OVERRIDE" 2 "CAN" 1 "RULE" 0 "DEFAULT" ;
VAL_ 1697 OUT2_Source 3 "OVERRIDE" 2 "CAN" 1 "RULE" 0 "DEFAULT" ;
VAL_ 1713 OUT2_Source 3 "OVERRIDE" 2 "CAN" 1 "RULE" 0 "DEFAULT" ;
VAL_ 1697 OUT3_Source 3 "OVERRIDE" 2 "CAN" 1 "RULE" 0 "DEFAULT" ;
VAL_ 1713 OUT3_Source 3 "OVERRIDE" 2 "CAN" 1 "RULE" 0 "DEFAULT" ;
VAL_ 1697 OUT4_Source 3 "OVERRIDE" 2 "CAN" 1 "RULE" 0 "DEFAULT" ;
VAL_ 1713 OUT4_Source 3 "OVERRIDE" 2 "CAN" 1 "RULE" 0 "DEFAULT" ;
VAL_ 1699 OUT1_Fault 13 "OVERVOLTAGE" 12 "FEEDBACK_MISMATCH" 11 "RUN_LIMIT" 10 "RETRY_WAIT" 9 "SLOT_MISMATCH" 8 "UNDERVOLTAGE" 7 "LOAD_SHED" 6 "LATCHED" 5 "EXT_VOLTAGE" 4 "OPEN_LOAD" 3 "OVERTEMP" 2 "SHORT" 1 "OVERCURRENT" 0 "NONE" ;
VAL_ 1715 OUT1_Fault 13 "OVERVOLTAGE" 12 "FEEDBACK_MISMATCH" 11 "RUN_LIMIT" 10 "RETRY_WAIT" 9 "SLOT_MISMATCH" 8 "UNDERVOLTAGE" 7 "LOAD_SHED" 6 "LATCHED" 5 "EXT_VOLTAGE" 4 "OPEN_LOAD" 3 "OVERTEMP" 2 "SHORT" 1 "OVERCURRENT" 0 "NONE" ;
VAL_ 1699 OUT2_Fault 13 "OVERVOLTAGE" 12 "FEEDBACK_MISMATCH" 11 "RUN_LIMIT" 10 "RETRY_WAIT" 9 "SLOT_MISMATCH" 8 "UNDERVOLTAGE" 7 "LOAD_SHED" 6 "LATCHED" 5 "EXT_VOLTAGE" 4 "OPEN_LOAD" 3 "OVERTEMP" 2 "SHORT" 1 "OVERCURRENT" 0 "NONE" ;
VAL_ 1715 OUT2_Fault 13 "OVERVOLTAGE" 12 "FEEDBACK_MISMATCH" 11 "RUN_LIMIT" 10 "RETRY_WAIT" 9 "SLOT_MISMATCH" 8 "UNDERVOLTAGE" 7 "LOAD_SHED" 6 "LATCHED" 5 "EXT_VOLTAGE" 4 "OPEN_LOAD" 3 "OVERTEMP" 2 "SHORT" 1 "OVERCURRENT" 0 "NONE" ;
VAL_ 1699 OUT3_Fault 13 "OVERVOLTAGE" 12 "FEEDBACK_MISMATCH" 11 "RUN_LIMIT" 10 "RETRY_WAIT" 9 "SLOT_MISMATCH" 8 "UNDERVOLTAGE" 7 "LOAD_SHED" 6 "LATCHED" 5 "EXT_VOLTAGE" 4 "OPEN_LOAD" 3 "OVERTEMP" 2 "SHORT" 1 "OVERCURRENT" 0 "NONE" ;
VAL_ 1715 OUT3_Fault 13 "OVERVOLTAGE" 12 "FEEDBACK_MISMATCH" 11 "RUN_LIMIT" 10 "RETRY_WAIT" 9 "SLOT_MISMATCH" 8 "UNDERVOLTAGE" 7 "LOAD_SHED" 6 "LATCHED" 5 "EXT_VOLTAGE" 4 "OPEN_LOAD" 3 "OVERTEMP" 2 "SHORT" 1 "OVERCURRENT" 0 "NONE" ;
VAL_ 1699 OUT4_Fault 13 "OVERVOLTAGE" 12 "FEEDBACK_MISMATCH" 11 "RUN_LIMIT" 10 "RETRY_WAIT" 9 "SLOT_MISMATCH" 8 "UNDERVOLTAGE" 7 "LOAD_SHED" 6 "LATCHED" 5 "EXT_VOLTAGE" 4 "OPEN_LOAD" 3 "OVERTEMP" 2 "SHORT" 1 "OVERCURRENT" 0 "NONE" ;
VAL_ 1715 OUT4_Fault 13 "OVERVOLTAGE" 12 "FEEDBACK_MISMATCH" 11 "RUN_LIMIT" 10 "RETRY_WAIT" 9 "SLOT_MISMATCH" 8 "UNDERVOLTAGE" 7 "LOAD_SHED" 6 "LATCHED" 5 "EXT_VOLTAGE" 4 "OPEN_LOAD" 3 "OVERTEMP" 2 "SHORT" 1 "OVERCURRENT" 0 "NONE" ;
VAL_ 1701 SLOT1_Class 3 "L" 2 "M" 1 "S" 0 "EMPTY" ;
VAL_ 1717 SLOT1_Class 3 "L" 2 "M" 1 "S" 0 "EMPTY" ;
VAL_ 1701 SLOT2_Class 3 "L" 2 "M" 1 "S" 0 "EMPTY" ;
VAL_ 1717 SLOT2_Class 3 "L" 2 "M" 1 "S" 0 "EMPTY" ;
VAL_ 1701 SLOT3_Class 3 "L" 2 "M" 1 "S" 0 "EMPTY" ;
VAL_ 1717 SLOT3_Class 3 "L" 2 "M" 1 "S" 0 "EMPTY" ;
VAL_ 1701 SLOT4_Class 3 "L" 2 "M" 1 "S" 0 "EMPTY" ;
VAL_ 1717 SLOT4_Class 3 "L" 2 "M" 1 "S" 0 "EMPTY" ;
VAL_ 1702 CfgReq_Op 5 "FACTORY_RESET" 4 "REVERT" 3 "COMMIT" 2 "WRITE" 1 "READ" 0 "NOP" ;
VAL_ 1718 CfgReq_Op 5 "FACTORY_RESET" 4 "REVERT" 3 "COMMIT" 2 "WRITE" 1 "READ" 0 "NOP" ;
VAL_ 1703 CfgResp_Status 5 "LOCKED" 4 "BUSY" 3 "READ_ONLY" 2 "OUT_OF_RANGE" 1 "UNKNOWN_PARAM" 0 "OK" ;
VAL_ 1719 CfgResp_Status 5 "LOCKED" 4 "BUSY" 3 "READ_ONLY" 2 "OUT_OF_RANGE" 1 "UNKNOWN_PARAM" 0 "OK" ;
VAL_ 1704 AUX1_Fault 13 "OVERVOLTAGE" 12 "FEEDBACK_MISMATCH" 11 "RUN_LIMIT" 10 "RETRY_WAIT" 8 "UNDERVOLTAGE" 7 "LOAD_SHED" 6 "LATCHED" 5 "EXT_VOLTAGE" 4 "OPEN_LOAD" 3 "OVERTEMP" 2 "SHORT" 1 "OVERCURRENT" 0 "NONE" ;
VAL_ 1720 AUX1_Fault 13 "OVERVOLTAGE" 12 "FEEDBACK_MISMATCH" 11 "RUN_LIMIT" 10 "RETRY_WAIT" 8 "UNDERVOLTAGE" 7 "LOAD_SHED" 6 "LATCHED" 5 "EXT_VOLTAGE" 4 "OPEN_LOAD" 3 "OVERTEMP" 2 "SHORT" 1 "OVERCURRENT" 0 "NONE" ;
VAL_ 1704 AUX2_Fault 13 "OVERVOLTAGE" 12 "FEEDBACK_MISMATCH" 11 "RUN_LIMIT" 10 "RETRY_WAIT" 8 "UNDERVOLTAGE" 7 "LOAD_SHED" 6 "LATCHED" 5 "EXT_VOLTAGE" 4 "OPEN_LOAD" 3 "OVERTEMP" 2 "SHORT" 1 "OVERCURRENT" 0 "NONE" ;
VAL_ 1720 AUX2_Fault 13 "OVERVOLTAGE" 12 "FEEDBACK_MISMATCH" 11 "RUN_LIMIT" 10 "RETRY_WAIT" 8 "UNDERVOLTAGE" 7 "LOAD_SHED" 6 "LATCHED" 5 "EXT_VOLTAGE" 4 "OPEN_LOAD" 3 "OVERTEMP" 2 "SHORT" 1 "OVERCURRENT" 0 "NONE" ;
VAL_ 1704 AUX3_Fault 13 "OVERVOLTAGE" 12 "FEEDBACK_MISMATCH" 11 "RUN_LIMIT" 10 "RETRY_WAIT" 8 "UNDERVOLTAGE" 7 "LOAD_SHED" 6 "LATCHED" 5 "EXT_VOLTAGE" 4 "OPEN_LOAD" 3 "OVERTEMP" 2 "SHORT" 1 "OVERCURRENT" 0 "NONE" ;
VAL_ 1720 AUX3_Fault 13 "OVERVOLTAGE" 12 "FEEDBACK_MISMATCH" 11 "RUN_LIMIT" 10 "RETRY_WAIT" 8 "UNDERVOLTAGE" 7 "LOAD_SHED" 6 "LATCHED" 5 "EXT_VOLTAGE" 4 "OPEN_LOAD" 3 "OVERTEMP" 2 "SHORT" 1 "OVERCURRENT" 0 "NONE" ;
VAL_ 1704 AUX4_Fault 13 "OVERVOLTAGE" 12 "FEEDBACK_MISMATCH" 11 "RUN_LIMIT" 10 "RETRY_WAIT" 8 "UNDERVOLTAGE" 7 "LOAD_SHED" 6 "LATCHED" 5 "EXT_VOLTAGE" 4 "OPEN_LOAD" 3 "OVERTEMP" 2 "SHORT" 1 "OVERCURRENT" 0 "NONE" ;
VAL_ 1720 AUX4_Fault 13 "OVERVOLTAGE" 12 "FEEDBACK_MISMATCH" 11 "RUN_LIMIT" 10 "RETRY_WAIT" 8 "UNDERVOLTAGE" 7 "LOAD_SHED" 6 "LATCHED" 5 "EXT_VOLTAGE" 4 "OPEN_LOAD" 3 "OVERTEMP" 2 "SHORT" 1 "OVERCURRENT" 0 "NONE" ;
VAL_ 1704 AUX1_State 3 "FAULT" 2 "PWM" 1 "ON" 0 "OFF" ;
VAL_ 1720 AUX1_State 3 "FAULT" 2 "PWM" 1 "ON" 0 "OFF" ;
VAL_ 1704 AUX2_State 3 "FAULT" 2 "PWM" 1 "ON" 0 "OFF" ;
VAL_ 1720 AUX2_State 3 "FAULT" 2 "PWM" 1 "ON" 0 "OFF" ;
VAL_ 1704 AUX3_State 3 "FAULT" 2 "PWM" 1 "ON" 0 "OFF" ;
VAL_ 1720 AUX3_State 3 "FAULT" 2 "PWM" 1 "ON" 0 "OFF" ;
VAL_ 1704 AUX4_State 3 "FAULT" 2 "PWM" 1 "ON" 0 "OFF" ;
VAL_ 1720 AUX4_State 3 "FAULT" 2 "PWM" 1 "ON" 0 "OFF" ;
VAL_ 1704 AUX1_Source 3 "OVERRIDE" 2 "CAN" 1 "RULE" 0 "DEFAULT" ;
VAL_ 1720 AUX1_Source 3 "OVERRIDE" 2 "CAN" 1 "RULE" 0 "DEFAULT" ;
VAL_ 1704 AUX2_Source 3 "OVERRIDE" 2 "CAN" 1 "RULE" 0 "DEFAULT" ;
VAL_ 1720 AUX2_Source 3 "OVERRIDE" 2 "CAN" 1 "RULE" 0 "DEFAULT" ;
VAL_ 1704 AUX3_Source 3 "OVERRIDE" 2 "CAN" 1 "RULE" 0 "DEFAULT" ;
VAL_ 1720 AUX3_Source 3 "OVERRIDE" 2 "CAN" 1 "RULE" 0 "DEFAULT" ;
VAL_ 1704 AUX4_Source 3 "OVERRIDE" 2 "CAN" 1 "RULE" 0 "DEFAULT" ;
VAL_ 1720 AUX4_Source 3 "OVERRIDE" 2 "CAN" 1 "RULE" 0 "DEFAULT" ;
VAL_ 1708 ResetReason 5 "FW_UPDATE" 4 "PIN" 3 "SOFTWARE" 2 "WATCHDOG" 1 "BROWN_OUT" 0 "POWER_ON" ;
VAL_ 1724 ResetReason 5 "FW_UPDATE" 4 "PIN" 3 "SOFTWARE" 2 "WATCHDOG" 1 "BROWN_OUT" 0 "POWER_ON" ;
